# STM32MP13xx register map
File version: 1.5
CPU: CA7 r0p0, little endian, MPU, FPU, 4 interrupt priority bits
Registers are 32-bit, read-write, reset 0x0 unless marked. A register's access mark holds for its fields unless they carry their own. Offsets are from the block's base; [hi:lo] are bit positions.

## CCU
Base 0x44010000
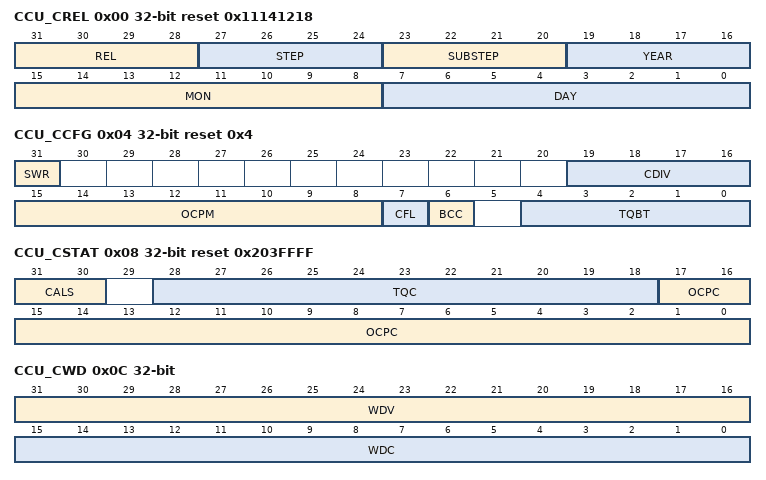
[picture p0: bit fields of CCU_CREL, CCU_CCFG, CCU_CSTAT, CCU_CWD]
0x00 CCU_CREL ro reset 0x11141218 — Clock calibration unit core release register
  [31:28] REL — Core release = 1
  [27:24] STEP — Step of core release = 1
  [23:20] SUBSTEP — Sub-step of core release = 1
  [19:16] YEAR — Timestamp year =
  [15:8] MON — Timestamp month = 12
  [7:0] DAY — Timestamp day = 18
0x04 CCU_CCFG reset 0x4 — Calibration configuration register
  [31] SWR — Software reset Writing a 1 to this bit resets the calibration FSM to state Not_Calibrated (FDCAN_CCU_CSTAT.CALS = 00). The calibration watchdog value CWD.WDV is also reset. Registers FDCAN_CCFG, FDCAN_CCU_CSTAT and the calibration watchdog configuration CWD.WDC are unchanged. The bit remains set until reset is completed. Write access by the Host CPU to registers/bits marked with âP=Protected Writeâ is possible only when the FDCAN control bits FDCAN_CCCR.CCE = 1 AND FDCAN_CCCR.INIT = 1.
  [19:16] CDIV — Clock divider The clock divider has to be configured when the clock calibration is bypassed (BCC = 1) to ensure that the FDCAN requirement is fulfilled. Write access by the Host CPU to registers/bits marked with âP=Protected Writeâ is possible only when the FDCAN control bits FDCAN_CCCR.CCE = 1 AND FDCAN_CCCR.INIT = 1.
    0=Divide by 1; 1=Divide by 2; 2=Divide by 4; 3=Divide by 6; 4=Divide by 8; 5=Divide by 10; 6=Divide by 12; 7=Divide by 14; 8=Divide by 16; 9=Divide by 18; 10=Divide by 20; 11=Divide by 22; 12=Divide by 24; 13=Divide by 26; 14=Divide by 28; 15=Divide by 30
  [15:8] OCPM — Oscillator clock periods minimum Configures the minimum number of periods in two CAN bit times. OCPM is used in basic calibration to avoid false measurements in case of glitches on the bus line. The configured number of periods is OCPM Ã 32. The configuration depends on the frequency and the bitrate configured in FDCAN modules (from 125 kbit/s up to 1 Mbit/s). It is recommended to configure a value slightly below two CAN bit times. The reset value is 1.6 bit times at 80 MHz fdcan_ker_ck and 1 Mbit/s CAN bitrate. Write access by the Host CPU to registers/bits marked with âP=Protected Writeâ is possible only when the FDCAN control bits FDCAN_CCCR.CCE = 1 AND FDCAN_CCCR.INIT = 1.
  [7] CFL — Calibration field length Write access by the Host CPU to registers/bits marked with âP=Protected Writeâ is possible only when the FDCAN control bits FDCAN_CCCR.CCE = 1 AND FDCAN_CCCR.INIT = 1.
    0=Calibration field length is 32 bits; 1=Calibration field length is 64 bits
  [6] BCC — Bypass clock calibration If this bit is set, the clock input fdcan_ker_ck is routed to the time quanta clock through a clock divider configurable via CDIV, cu_cok is always 1. In this case the baudrate prescaler of the connected FDCANs has to be configured to generate the FDCAN internal time quanta clock.
    0=Clock calibration unit generates time quanta clock; 1=Clock calibration unit bypassed (default configuration)
  [4:0] TQBT — Time quanta per bit time Configures the number of time quanta per bit time. Same value as configured in FDCAN modules. The range of the resulting time quanta clock fdcan_tq_ck is from 0.5 MHz (bitrate of 125 kbit/s with 4 tq per bit time) to 25 MHz (bitrate of 1 Mbit/s with 25 tq per bit time). Valid values are 4 to 25. Configured values below 4 are interpreted as 4, values above 25 are interpreted as 25. Write access by the Host CPU to registers/bits marked with âP=Protected Writeâ is possible only when the FDCAN control bits FDCAN_CCCR.CCE = 1 AND FDCAN_CCCR.INIT = 1.
0x08 CCU_CSTAT ro reset 0x203FFFF — Calibration status register
  [31:30] CALS — Calibration state
    0=Not_Calibrated; 1=Basic_Calibrated; 2=Precision_Calibrated
  [28:18] TQC — Time quanta counter Captured number of time quanta in calibration field (32 or 64 bits). Only valid when the clock calibration unit is in state Precision_Calibrated.
  [17:0] OCPC — Oscillator clock period counter Captured number of oscillator clock periods in calibration field (32 or 64 bits). Only valid when the clock calibration unit is in state Precision_Calibrated.
0x0C CCU_CWD access per field — Calibration watchdog register
  [31:16] WDV ro — Watchdog value Actual calibration watchdog counter value.
  [15:0] WDC rw — WDC Watchdog configuration Start value of the calibration watchdog counter. With the reset value of 00 the counter is disabled. Write access by the Host CPU to registers/bits marked with âP = Protected Writeâ is possible only when the FDCAN control bits FDCAN_CCCR.CCE = 1 AND FDCAN_CCCR.INIT = 1.
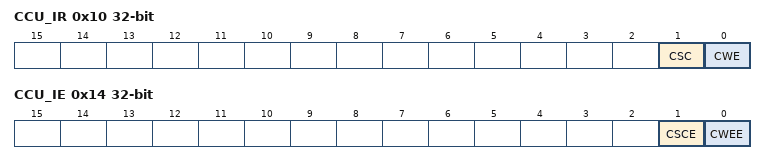
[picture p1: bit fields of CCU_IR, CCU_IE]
0x10 CCU_IR — Clock calibration unit interrupt register
  [1] CSC — Calibration state changed
    0=Calibration state unchanged; 1=Calibration state has changed
  [0] CWE — Calibration watchdog event
    0=No calibration watchdog event; 1=Calibration watchdog event occurred
0x14 CCU_IE — Clock calibration unit interrupt enable register
  [1] CSCE — Calibration state changed enable
    0=Interrupt disabled; 1=Interrupt enabled
  [0] CWEE — Calibration watchdog event enable
    0=Interrupt disabled; 1=Interrupt enabled

## Notices in the file
Copyright (c) 2024 STMicroelectronics.
SPDX-License-Identifier: Apache-2.0
Licensed under the Apache License, Version 2.0 (the "License");
you may not use this file except in compliance with the License.
You may obtain a copy of the License at
http://www.apache.org/licenses/LICENSE-2.0
Unless required by applicable law or agreed to in writing, software
distributed under the License is distributed on an "AS IS" BASIS,
WITHOUT WARRANTIES OR CONDITIONS OF ANY KIND, either express or implied.
See the License for the specific language governing permissions and
limitations under the License.
